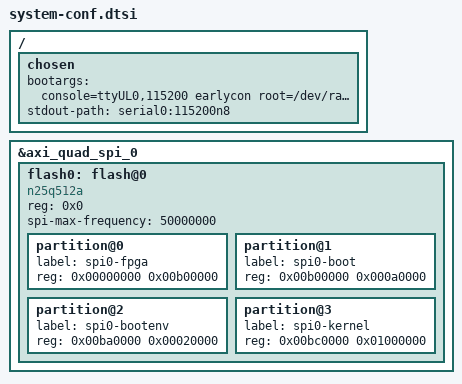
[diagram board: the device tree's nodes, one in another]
/*
 * CAUTION: This file is automatically generated by PetaLinux SDK.
 * DO NOT modify this file
 */


/ {
	chosen {
		bootargs = "console=ttyUL0,115200 earlycon root=/dev/ram0 rw init_fatal_sh=1";
		stdout-path = "serial0:115200n8";
	};
};

&axi_quad_spi_0 {
	#address-cells = <1>;
	#size-cells = <0>;
	flash0: flash@0 {
		compatible = "n25q512a","jedec,spi-nor";
		reg = <0x0>;
		#address-cells = <1>;
		#size-cells = <1>;
		spi-max-frequency = <50000000>;
		partition@0 {
			label = "spi0-fpga";
			reg = <0x00000000 0x00b00000>;
		};
		partition@1 {
			label = "spi0-boot";
			reg = <0x00b00000 0x000a0000>;
		};
		partition@2 {
			label = "spi0-bootenv";
			reg = <0x00ba0000 0x00020000>;
		};
		partition@3 {
			label = "spi0-kernel";
			reg = <0x00bc0000 0x01000000>;
		};
	};
};

